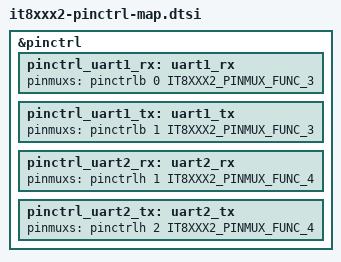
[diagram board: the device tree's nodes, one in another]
/*
 * Copyright (c) 2022 ITE Corporation. All Rights Reserved.
 *
 * SPDX-License-Identifier: Apache-2.0
 */

#include <dt-bindings/pinctrl/it8xxx2-pinctrl.h>

&pinctrl {
	/* UART alternate function */
	pinctrl_uart1_rx: uart1_rx {
		pinmuxs = <&pinctrlb 0 IT8XXX2_PINMUX_FUNC_3>;
	};
	pinctrl_uart1_tx: uart1_tx {
		pinmuxs = <&pinctrlb 1 IT8XXX2_PINMUX_FUNC_3>;
	};
	pinctrl_uart2_rx: uart2_rx {
		pinmuxs = <&pinctrlh 1 IT8XXX2_PINMUX_FUNC_4>;
	};
	pinctrl_uart2_tx: uart2_tx {
		pinmuxs = <&pinctrlh 2 IT8XXX2_PINMUX_FUNC_4>;
	};

};
